# FX1 register map
Vendor: FTEL; File version: VP_FX1_V3.0_ISP_1.07
Registers are 32-bit, read-write, reset 0x0 unless marked. A register's access mark holds for its fields unless they carry their own. Offsets are from the block's base; [hi:lo] are bit positions; 'fields as' and 'values as' point back to an identical list; <NAME> marks a mode.

## ISP (part 2 of 4) — ISP FX1 v1.07; đủ register/field từ sheet Flat Registers của CSR. Địa chỉ base theo BSP VP_FX1_V3.0; không thay thế xác nhận map silicon.
Base 0x11000000
0x1808 NR_2D_STATUS ro — NR: block status. [access=ro]
  [0] BUSY — The 2D Noise-Reduction Block Busy 1 while the block itself holds pixels: the block's own busy, as defined in its MAS section. It can read 0 inside a frame (line fill, input gaps), so it does not show that a frame has drained; use COMMON_STATUS.BUSY = 0 for no frame in flight. Follow the block-specific configuration and LUT loading sequence; busy alone does not grant permission to rewrite live tables. [access=ro]
0x1A00 TNR_3D_CTRL — TNR_3D: reserved for a future temporal noise-reduction function. Register storage is present; writes have no image-processing effect in this MAS. [access=rw]
  [0] EN — Temporal NR Enable (not implemented) Reserved; no processing effect in this MAS. [access=rw]
0x1A04 TNR_3D_MTF_SEL — TNR_3D: motion transfer function preset. NOT IMPLEMENTED -- see TNR_3D_CTRL. [access=rw]
  [2:0] MTF — Motion Transfer Preset (not implemented) Reserved; no processing effect in this MAS. 0 = none, 1 = weak, 2 = medium, 3 = strong, 4 = aggressive. [access=rw]
0x1A08 TNR_3D_HIST_BASE — TNR_3D: DDR base address of the history frame. NOT IMPLEMENTED -- see TNR_3D_CTRL. [access=rw]
  [31:0] HIST_BASE_ADDR — History Frame Base Address (not implemented) Reserved; no processing effect in this MAS. [access=rw]
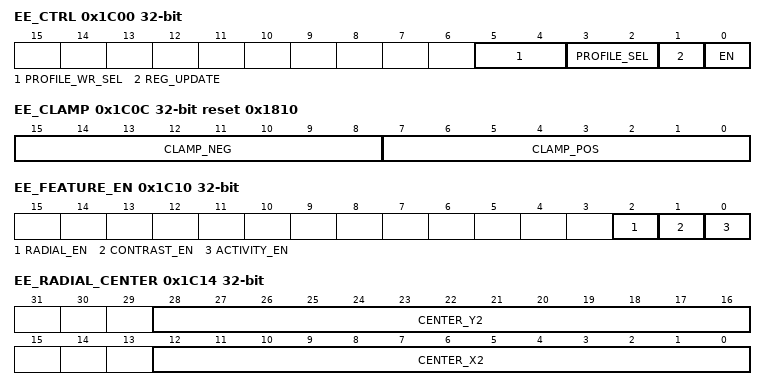
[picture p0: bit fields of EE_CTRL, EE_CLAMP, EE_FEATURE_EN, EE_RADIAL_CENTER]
0x1C00 EE_CTRL — EE: edge enhancement control. Sharpens by adding back a clamped, gain-shaped high-pass of the luma at two scales. [access=rw]
  [5:4] PROFILE_WR_SEL — Live resident programming/readback selector 0..2. Code 3 discards writes and reads profile 0. Not banked by TUNE_BANK. [access=rw]
  [3:2] PROFILE_SEL — Active Parameter Profile Select 0..2 select one of three resident tuning profiles. Captured at accepted window-centre SOF. Code 3 selects profile 0. Separate from PROFILE_WR_SEL. In profile mode, the ingress token supplies the bank enable and resident selection; local SOF uses that captured token. [access=rw]
  [1] REG_UPDATE — Reserved Update Control Readable/writable compatibility field; no explicit commit command. Enable, selected profile and scalar configuration are captured at the accepted window-centre SOF. In profile mode, the ingress token supplies the bank enable and resident selection; local SOF uses that captured token. [access=rw]
  [0] EN — Edge Enhancement Enable 1 = sharpen, 0 = delayed pass-through (the latency is unchanged). [access=rw]
0x1C04 EE_ALPHA reset 0x4000 — EE: fine-scale (3x3) sharpening strength. Resident scalar: PROFILE_WR_SEL selects both read and write; outside TUNE_BANK. Writes clear confirmation and are blocked while active, sealed, pending or referenced in profile mode. [access=rw]
  [15:0] ALPHA — Fine-Scale Sharpening Strength UQ1.15; 0x8000 = 1.0 and is the maximum. Larger values are clamped to 1.0 by the hardware rather than wrapping. External: the value is held outside the CSR block; the type is the bus behaviour. [access=rw]
0x1C08 EE_BETA reset 0x2000 — EE: coarse-scale (5x5) sharpening strength. Resident scalar: PROFILE_WR_SEL selects both read and write; outside TUNE_BANK. Writes clear confirmation and are blocked while active, sealed, pending or referenced in profile mode. [access=rw]
  [15:0] BETA — Coarse-Scale Sharpening Strength UQ1.15; 0x8000 = 1.0 and is the maximum, clamped as ALPHA is. The coarse term broadens the halo; usually set below ALPHA. External: the value is held outside the CSR block; the type is the bus behaviour. [access=rw]
0x1C0C EE_CLAMP reset 0x1810 — EE: limits on how far one pixel may be moved. The asymmetry is deliberate -- overshoot on the bright side of an edge is more visible than undershoot, so the positive clamp is usually the smaller. Resident scalar: PROFILE_WR_SEL selects both read and write; outside TUNE_BANK. Writes clear confirmation and are blocked while active, sealed, pending or referenced in profile mode. [access=rw]
  [15:8] CLAMP_NEG — Negative Correction Limit Largest negative correction, in 8-bit luma counts. External: the value is held outside the CSR block; the type is the bus behaviour. [access=rw]
  [7:0] CLAMP_POS — Positive Correction Limit Largest positive correction, in 8-bit luma counts. External: the value is held outside the CSR block; the type is the bus behaviour. [access=rw]
0x1C10 EE_FEATURE_EN — EE: optional activity, contrast and radial gain modulation. With all three disabled, correction still uses ALPHA/BETA and the always-applied luma LUT; disabled optional modulations contribute unity. Resident scalar: PROFILE_WR_SEL selects both read and write; outside TUNE_BANK. Writes clear confirmation and are blocked while active, sealed, pending or referenced in profile mode. [access=rw]
  [2] RADIAL_EN — Radial Modulation Enable 1 = modulate by distance from the image centre, using the R2 thresholds and the four radial gains. Lets the corners be sharpened differently from the centre. External: the value is held outside the CSR block; the type is the bus behaviour. [access=rw]
  [1] CONTRAST_EN — Contrast Modulation Enable 1 = modulate by local contrast, from the CPOS and CNEG LUTs. Separate tables for positive and negative excursions. External: the value is held outside the CSR block; the type is the bus behaviour. [access=rw]
  [0] ACTIVITY_EN — Activity Modulation Enable 1 = modulate by local activity, from the ACT LUT. Suppresses sharpening in flat areas, where it would only amplify noise. External: the value is held outside the CSR block; the type is the bus behaviour. [access=rw]
0x1C14 EE_RADIAL_CENTER — EE: centre of the radial falloff. Held at twice the coordinate so the centre can sit on a half-pixel, which matters for an even-sized frame whose true centre is between pixels. Resident scalar: PROFILE_WR_SEL selects both read and write; outside TUNE_BANK. Writes clear confirmation and are blocked while active, sealed, pending or referenced in profile mode. [access=rw]
  [28:16] CENTER_Y2 — Radial Centre Row (x2) Twice the centre row. External: the value is held outside the CSR block; the type is the bus behaviour. [access=rw]
  [12:0] CENTER_X2 — Radial Centre Column (x2) Twice the centre column. For a 1920-wide frame the centre is 1919/2, so this is 1919. External: the value is held outside the CSR block; the type is the bus behaviour. [access=rw]
0x1C18 EE_RADIAL_R2_TH0 — EE: radial zone boundary 0. Squared distance, so no square root is needed in the datapath. Resident scalar: PROFILE_WR_SEL selects both read and write; outside TUNE_BANK. Writes clear confirmation and are blocked while active, sealed, pending or referenced in profile mode. [access=rw]
  [26:0] R2_TH0 — Radial Zone 0 Boundary Squared radius at which zone 0 ends, in units of (2*pixel)^2 to match the doubled centre coordinates. External: the value is held outside the CSR block; the type is the bus behaviour. [access=rw]
0x1C1C EE_RADIAL_R2_TH1 — EE: radial zone boundary 1. Squared distance, so no square root is needed in the datapath. Resident scalar: PROFILE_WR_SEL selects both read and write; outside TUNE_BANK. Writes clear confirmation and are blocked while active, sealed, pending or referenced in profile mode. [access=rw]
  [26:0] R2_TH1 — Radial Zone 1 Boundary Squared radius at which zone 1 ends, in units of (2*pixel)^2 to match the doubled centre coordinates. Must not be below R2_TH0. Zones are tested in order and the first match wins; in profile mode SEAL rejects decreasing thresholds with RADIAL_EN=1 (INVALID). External: the value is held outside the CSR block; the type is the bus behaviour. [access=rw]
0x1C20 EE_RADIAL_R2_TH2 — EE: radial zone boundary 2. Squared distance, so no square root is needed in the datapath. Resident scalar: PROFILE_WR_SEL selects both read and write; outside TUNE_BANK. Writes clear confirmation and are blocked while active, sealed, pending or referenced in profile mode. [access=rw]
  [26:0] R2_TH2 — Radial Zone 2 Boundary Squared radius at which zone 2 ends, in units of (2*pixel)^2 to match the doubled centre coordinates. Must not be below R2_TH1. Zones are tested in order and the first match wins; in profile mode SEAL rejects decreasing thresholds with RADIAL_EN=1 (INVALID). External: the value is held outside the CSR block; the type is the bus behaviour. [access=rw]
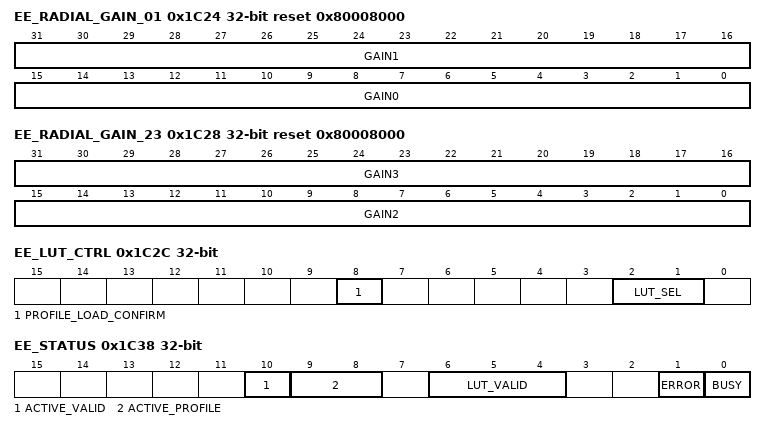
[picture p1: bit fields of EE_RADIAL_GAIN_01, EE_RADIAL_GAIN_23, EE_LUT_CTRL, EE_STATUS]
0x1C24 EE_RADIAL_GAIN_01 reset 0x80008000 — EE: radial gains for the innermost two zones. Resident scalar: PROFILE_WR_SEL selects both read and write; outside TUNE_BANK. Writes clear confirmation and are blocked while active, sealed, pending or referenced in profile mode. [access=rw]
  [31:16] GAIN1 — Radial Gain, Zone 1 UQ1.15 gain applied between R2_TH0 and R2_TH1; 0x8000 = 1.0 = no change. External: the value is held outside the CSR block; the type is the bus behaviour. [access=rw]
  [15:0] GAIN0 — Radial Gain, Innermost Zone UQ1.15 gain applied inside R2_TH0; 0x8000 = 1.0 = no change. External: the value is held outside the CSR block; the type is the bus behaviour. [access=rw]
0x1C28 EE_RADIAL_GAIN_23 reset 0x80008000 — EE: radial gains for the outer two zones. Resident scalar: PROFILE_WR_SEL selects both read and write; outside TUNE_BANK. Writes clear confirmation and are blocked while active, sealed, pending or referenced in profile mode. [access=rw]
  [31:16] GAIN3 — Radial Gain, Outermost Zone UQ1.15 gain applied beyond R2_TH2; 0x8000 = 1.0 = no change. External: the value is held outside the CSR block; the type is the bus behaviour. [access=rw]
  [15:0] GAIN2 — Radial Gain, Zone 2 UQ1.15 gain applied between R2_TH1 and R2_TH2; 0x8000 = 1.0 = no change. External: the value is held outside the CSR block; the type is the bus behaviour. [access=rw]
0x1C2C EE_LUT_CTRL — Live EE table selector and resident confirmation port. Scalar or LUT writes clear destination validity. Confirmation requires complete scalars/tables and mode-specific ownership: unreferenced in profile mode, disabled/idle in legacy mode. [access=mixed]
  [8] PROFILE_LOAD_CONFIRM wo write-1-sets — Confirm complete resident scalars and four LUTs. Profile mode: destination unreferenced by active/sealed/pending/in-flight state. Legacy: EE disabled/idle. Same-edge scalar/LUT write wins and leaves invalid. [access=w1p]
  [2:1] LUT_SEL — Gain Table Bank Select Also selects which bank EE_LUT_RDATA reads. 0x0 = LUMA (Luma table, 64 entries) 0x1 = ACTIVITY (Activity table, 64 entries) 0x2 = CONTRAST_POS (Contrast-positive table, 32 entries) 0x3 = CONTRAST_NEG (Contrast-negative table, 32 entries) [access=rw]
0x1C30 EE_LUT_ADDR — EE: gain table index. Auto-increments on every write to EE_LUT_WDATA. [access=rw]
  [5:0] LUT_ADDR — Gain Table Index Entry index. 0..63 for the luma and activity tables, 0..31 for the two contrast tables, where the top bit is ignored. [access=rw]
0x1C34 EE_LUT_WDATA — EE: gain table write port. [access=rw]
  [15:0] LUT_WDATA — Gain Table Write Data UQ1.15; 0x8000 = 1.0. Each selected profile owns its tables. RAM contents are undefined after reset: load every required entry before enabling EE. Values above 1.0 clamp on use. Readback uses EE_LUT_RDATA. [access=rw]
0x1C38 EE_STATUS — EE status. LUT_VALID reports confirmed profiles. An invalid selected profile bypasses correction without reading undefined SRAM contents. [access=mixed]
  [10] ACTIVE_VALID ro — One after a local SOF selected a confirmed resident; zero until then or after its validity is cleared. Separate from block busy and enable. [access=ro]
  [9:8] ACTIVE_PROFILE ro — Resident selection captured for the most recent accepted local EE SOF; does not follow PROFILE_WR_SEL. 0..2; zero after hard/common reset. [access=ro]
  [6:4] LUT_VALID ro — Confirmed resident scalars and four LUTs for profiles 0..2. Scalar/LUT writes or input-domain changes clear destination validity; hard reset and profile-mode common reset clear all. Invalid selected profile bypasses enhancement. [access=ro]
  [1] ERROR write-1-clears — Radial Gain Range Error Sticky W1C. Sets once per processed frame when EE and radial gain are enabled and an active-profile radial gain exceeds 1.5 (0xC000). The gain clamps to 1.5 on use. A simultaneous new event wins over clear. [access=w1c]
  [0] BUSY ro — EE Busy 1 while the block itself holds pixels: the block's own busy, as defined in its MAS section. It can read 0 inside a frame (line fill, input gaps), so it does not show that a frame has drained; use COMMON_STATUS.BUSY = 0 for no frame in flight. Profile mode protects active/sealed/pending/referenced residents; another unreferenced resident may be loaded. [access=ro]
0x1C3C EE_LUT_RDATA ro — EE: gain table readback selected by PROFILE_WR_SEL, EE_LUT_CTRL.LUT_SEL and EE_LUT_ADDR. Programming selector 3 reads profile 0. Contents are undefined until loaded. [access=ro]
  [15:0] RDATA — Gain Table Read Data Contents of the selected table entry. [access=ro]
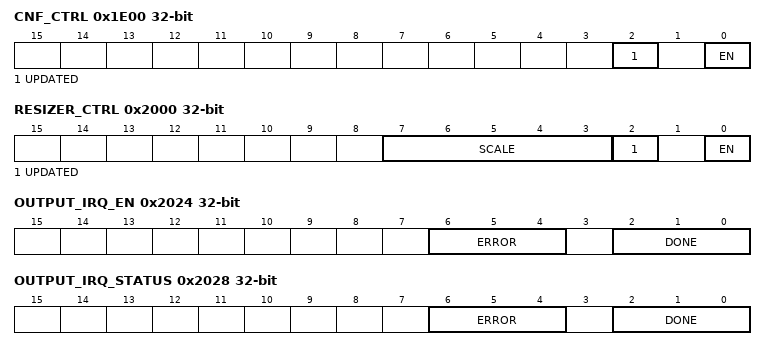
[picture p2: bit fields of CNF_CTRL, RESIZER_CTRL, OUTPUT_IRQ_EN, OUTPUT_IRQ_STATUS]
0x1E00 CNF_CTRL — CNF: chroma noise filter control. A 5x5 luma-guided filter (guided image filter, radius 2): chroma is fitted as a local linear function of luma, so noise is averaged in flat areas while chroma edges that coincide with luma edges are kept. [access=rw]
  [2] UPDATED — Reserved Update Control Readable/writable compatibility field with no commit effect. Enable and CNF_GF_EPS are sampled at accepted SOF. [access=rw]
  [0] EN — Chroma Noise Filter Enable 1 = filter chroma, 0 = pass through unchanged. [access=rw]
0x1E04 CNF_GF_EPS reset 0xC8 — CNF: guided-filter regularisation epsilon. Larger values smooth chroma more and keep fewer weak edges. [access=rw]
  [15:0] GF_EPS — Guided Filter Epsilon 0..65535, in 8-bit luma units squared. Windows whose luma variance is well below epsilon are smoothed; windows well above it keep chroma following luma. Every code is legal. [access=rw]
0x1E0C CNF_STRENGTH — CNF: reserved strength control. The specified filter uses enable and CNF_GF_EPS; this field has no processing effect. [access=rw]
  [1:0] MODE_STRENGTH — Filter Strength (not implemented) Reserved; no processing effect in this MAS. [access=rw]
0x1E10 CNF_STATUS ro — CNF: block status, read-only. [access=ro]
  [0] BUSY — Chroma Noise Filter Busy 1 while the block itself holds pixels: the block's own busy, as defined in its MAS section. It can read 0 inside a frame (line fill, input gaps), so it does not show that a frame has drained; use COMMON_STATUS.BUSY = 0 for no frame in flight. Follow the block-specific configuration and LUT loading sequence; busy alone does not grant permission to rewrite live tables. [access=ro]
0x2000 RESIZER_CTRL — CH0 NV12 output resizer control, maximum output 3840x2160. The unprefixed RESIZER_* registers belong to CH0. Input is the post-IQ crop for this channel; the crop may be larger than the output. No upscaling or custom target sizes. Reject invalid targets before DMA arm; no silent FullRes fallback. Wait for channel OUT_W/H to settle. [access=rw]
  [7:3] SCALE — CH0 NV12 preset selector [7:3]. 0=FullRes crop bypass; 1..14 established presets; 16=640x640, 17=640x384, 18=640x352, 19=512x512, 20=416x416, 21=320x320. Codes 15 and 22..31 reserved. Maximum output 3840x2160. Output must not exceed crop dimensions. No upscaling. [access=rw]
  [2] UPDATED — Legacy software update hint; readable storage with no commit effect. Active size, crop, enable and SCALE changes trigger geometry derivation. Custom-size words are reserved. Wait for OUT_W/H to settle before arming DMA; capture geometry at SOF. [access=rw]
  [0] EN — CH0 resizer enable. 1 selects SCALE; 0 bypasses scaling and preserves crop size. Both paths must fit the 3840x2160 output limit. Change geometry only after stop/drain; validate before DMA arm. [access=rw]
0x2004 RESIZER_CUSTOM_W ro — Deprecated target-size address. Reserved in ABI 1.07; reads zero and ignores writes. Programmable custom resizing is not supported. [access=ro]
  [31:0] RESERVED — Reads zero; writes ignored. [access=ro]
0x2008 RESIZER_CUSTOM_H ro — Deprecated target-size address. Reserved in ABI 1.07; reads zero and ignores writes. Programmable custom resizing is not supported. [access=ro]
  [31:0] RESERVED — Reads zero; writes ignored. [access=ro]
0x2014 RESIZER_OUT_W ro — Validated derived output dimension. Reset zero; may retain the last completed value while geometry is invalid. Check the channel GEOMETRY_STATUS before arming DMA. [access=ro]
  [12:0] OUT_WIDTH
0x2018 RESIZER_OUT_H ro — Validated derived output dimension. Reset zero; may retain the last completed value while geometry is invalid. Check the channel GEOMETRY_STATUS before arming DMA. [access=ro]
  [12:0] OUT_HEIGHT
0x201C RESIZER_STATUS ro — RESIZER: block status. [access=ro]
  [0] BUSY — Resizer Busy 1 while the block itself holds pixels: the block's own busy, as defined in its MAS section. It can read 0 inside a frame (line fill, input gaps), so it does not show that a frame has drained; use COMMON_STATUS.BUSY = 0 for no frame in flight. Follow the block-specific configuration and LUT loading sequence; busy alone does not grant permission to rewrite live tables. [access=ro]
0x2020 OUTPUT_ENABLE reset 0x1 — Enabled output channels. Defaults to CH0. Accepted SOF snapshots mask at distributor. Enabled channels share lossless backpressure. [access=rw]
  [2:0] CHANNELS — Bit 0 Preview NV12, bit 1 Video NV12, bit 2 NPU RGB888. Change only with input stopped and all output paths drained. [access=rw]
0x2024 OUTPUT_IRQ_EN — Per-output interrupt enables. [access=rw]
  [6:4] ERROR — Mask bit for error events. Field bits 0..2 correspond to CH0..CH2. One enables interrupt contribution; zero masks it. [access=rw]
  [2:0] DONE — Mask bit for completion events. Field bits 0..2 correspond to CH0..CH2. One enables interrupt contribution; zero masks it. [access=rw]
0x2028 OUTPUT_IRQ_STATUS write-1-clears — Per-output completion and error events; hardware set dominates software clear. Completion waits for write responses. [access=w1c]
  [6:4] ERROR write-1-clears — Sticky W1C error events; bit c sets when a recovery retires an enabled channel-c output without DONE. Field bits 0..2 correspond to CH0..CH2. Hardware set wins over clear. Clearing the event does not release buffer ownership. [access=w1c]
  [2:0] DONE write-1-clears — Sticky W1C completion events; bit c sets when channel c publishes ODMA_BUF_DONE. Field bits 0..2 correspond to CH0..CH2. Hardware set wins over clear. Clearing the event does not release buffer ownership. [access=w1c]
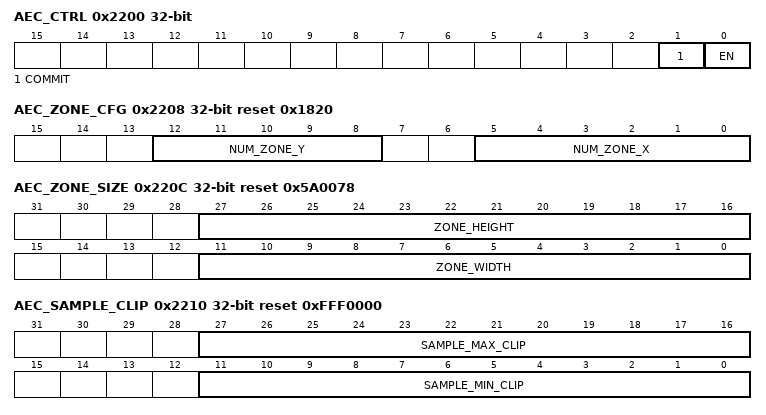
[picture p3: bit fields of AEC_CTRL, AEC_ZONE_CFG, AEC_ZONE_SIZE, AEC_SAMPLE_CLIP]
0x2200 AEC_CTRL — AEC: auto-exposure statistics control. The block only measures -- it does not drive exposure. Software reads the sums, counts and histogram and decides what to ask the sensor for. [access=mixed]
  [1] COMMIT write-1-sets — Configuration Commit Write 1 to transfer the shadowed enable, zone geometry, clip limits and thresholds at the next accepted ingress SOF. Self-clears on transfer. Active image height is captured per frame and is not shadowed by this command. [access=w1s]
  [0] EN — AE Statistics Enable 1 = accumulate statistics, 0 = idle. [access=rw]
0x2204 AEC_CONTEXT_ID — AEC: software tag carried with the statistics. Exposure changes take effect some frames after they are requested, so the tag is how software tells which request a result belongs to: write it here, read it back from AEC_RESULT_CONTEXT_ID with the matching frame. [access=rw]
  [31:0] CONTEXT_ID — Exposure Context Tag Software value captured at ingress SOF and associated with that frame. Write before admitting the frame; publication exposes it in AEC_RESULT_CONTEXT_ID. [access=rw]
0x2208 AEC_ZONE_CFG reset 0x1820 — AEC: zone grid. The frame is divided into a grid and each zone accumulates independently, so software can weight the metering however it likes. [access=rw]
  [12:8] NUM_ZONE_Y — Vertical Zone Count Vertical zones, 1..24. With the maximum grid there are 768 zones. [access=rw]
  [5:0] NUM_ZONE_X — Horizontal Zone Count Horizontal zones, 1..32. [access=rw]
0x220C AEC_ZONE_SIZE reset 0x5A0078 — AEC: nominal nonzero zone dimensions, 1..4095 each. Require (Nx-1)*zone_width < active_width <= Nx*zone_width and similarly in Y. The last zone covers the remainder. A single full-frame zone is legal; use authoritative 64-bit results rather than narrow low-bit projections. [access=rw]
  [27:16] ZONE_HEIGHT — Nominal Zone Height Nominal zone height in lines. [access=rw]
  [11:0] ZONE_WIDTH — Nominal Zone Width Nominal zone width in pixels. [access=rw]
0x2210 AEC_SAMPLE_CLIP reset 0xFFF0000 — Inclusive RAW12 Bayer sum/count qualification bounds, 0..4095. MIN <= MAX required. Extrema and histograms observe all measured samples independently of these clips. [access=rw]
  [27:16] SAMPLE_MAX_CLIP — Maximum qualifying RAW12 Bayer value, inclusive; valid range 0..4095; invalid values disable the frame measurement. [access=rw]
  [11:0] SAMPLE_MIN_CLIP — Minimum qualifying RAW12 Bayer value, inclusive; valid range 0..4095; invalid values disable the frame measurement. [access=rw]
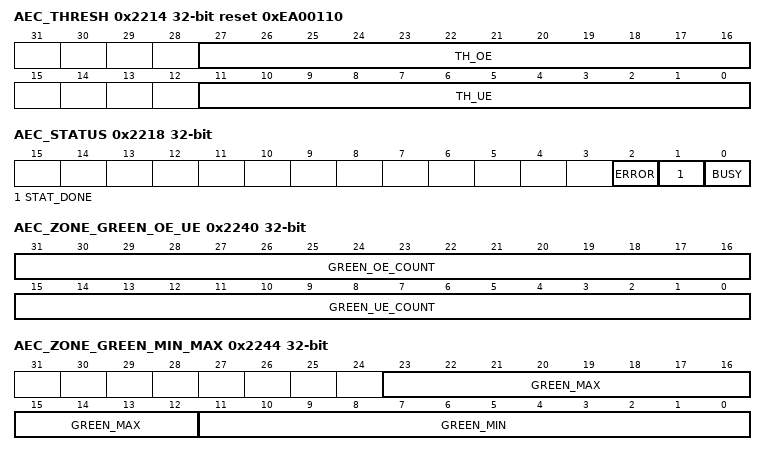
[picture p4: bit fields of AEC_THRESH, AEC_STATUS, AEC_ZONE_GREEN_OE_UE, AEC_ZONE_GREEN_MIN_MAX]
0x2214 AEC_THRESH reset 0xEA00110 — AEC: RAW12 Bayer threshold settings for per-zone over/under counts. OE increments for S>TH_OE; UE increments for S<TH_UE, independently of sum clipping. Any value above 4095 disables that frame measurement. [access=rw]
  [27:16] TH_OE — Strict RAW12 overexposure classification: sample > threshold. Startup 3744; programmable and sensor-calibrated. Require UE < OE. [access=rw]
  [11:0] TH_UE — Strict RAW12 underexposure classification: sample < threshold. Startup 272; programmable and sensor-calibrated. Require UE < OE. [access=rw]
0x2218 AEC_STATUS — AEC: block status. [access=mixed]
  [2] ERROR write-1-clears — AE Statistics Error (not implemented) Reads 0; not set by hardware. Software detects a missed frame from AEC_FRAME_ID. [access=w1c]
  [1] STAT_DONE write-1-clears — Statistics Ready Sticky W1C completion event. Results and identity publish atomically into a READY bank. ACQUIRE before reading; RELEASE after copying. Clearing STAT_DONE acknowledges the event and does not release the bank. Hardware completion wins over simultaneous clear. [access=w1c]
  [0] BUSY ro — AE Statistics Busy 1 = a frame is being accumulated. [access=ro]
0x221C AEC_FRAME_ID ro — AEC: ingress frame identifier of the leased result bank, read-only. [access=ro]
  [31:0] FRAME_ID — Shared ingress-SOF frame number of the leased statistics. First admitted frame after hard reset is 1; wraps modulo 2^32. Common and DMA soft resets preserve the counter. Metadata remains stable until RELEASE; no lease returns zero and sets the ownership error. [access=ro]
0x2220 AEC_RESULT_CONTEXT_ID ro — AEC: software context tag published with the leased statistics frame; stable until RELEASE. [access=ro]
  [31:0] CONTEXT_ID — Captured photometric configuration epoch for the measured frame. [access=ro]
0x2224 AEC_CHANNEL_SEL — Legacy readout selector: 0 aggregate Bayer statistics; 1..3 return zero rather than per-CFA results. This is not the AE source tap selector; use TUNE_AEC_SOURCE. [access=rw]
  [1:0] CHANNEL_SEL
0x2228 AEC_GLOBAL_SUM_LO ro — AEC: whole-frame qualified RAW12 Bayer sum, low word, read-only. Narrow readback is a low-bit modulo projection from the same acquired lease; use the 64-bit indirect readout for authoritative totals. No-lease reads return zero and set NO_LEASE. [access=ro]
  [31:0] GLOBAL_SUM_LO — Frame Sum, Low Word Bits [31:0] of the qualified sum. [access=ro]
0x222C AEC_GLOBAL_SUM_HI ro — AEC: whole-frame qualified RAW12 Bayer sum, high bits, read-only; retained width for map compatibility. Narrow readback is a low-bit modulo projection from the same acquired lease; use the 64-bit indirect readout for authoritative totals. No-lease reads return zero and set NO_LEASE. [access=ro]
  [0] GLOBAL_SUM_HI — Frame Sum, High Bit Bit [32] of the qualified sum. [access=ro]
0x2230 AEC_GLOBAL_COUNT ro — AEC: number of RAW12 Bayer samples contributing to the qualified global sum, read-only. The count excludes samples outside the inclusive clip bounds. Narrow readback is a low-bit modulo projection from the same acquired lease; use the 64-bit indirect readout for authoritative totals. No-lease reads return zero and set NO_LEASE. [access=ro]
  [22:0] GLOBAL_COUNT — Frame qualified RAW12 Bayer sample count. [access=ro]
0x2234 AEC_ZONE_ADDR — AEC: zone read selector, 0..767 in raster order. Narrow results project the same acquired bank as the 64-bit port. Two result banks preserve READY/LEASED data while another frame is collected; never reuse results before RELEASE. [access=rw]
  [9:0] ZONE_ADDR — Readout Zone Select Zone index 0..767, in raster order: y * num_zone_x + x. [access=rw]
0x2238 AEC_ZONE_SUM ro — AEC: qualified RAW12 Bayer sum for the selected zone, read-only. Narrow readback is a low-bit modulo projection from the same acquired lease; use the 64-bit indirect readout for authoritative totals. No-lease reads return zero and set NO_LEASE. [access=ro]
  [27:0] ZONE_SUM — Zone Sum Qualified sum for the zone at AEC_ZONE_ADDR. [access=ro]
0x223C AEC_ZONE_COUNT ro — AEC: qualified RAW12 Bayer sample count for the selected zone, read-only; wraps modulo 65,536. Narrow readback is a low-bit modulo projection from the same acquired lease; use the 64-bit indirect readout for authoritative totals. No-lease reads return zero and set NO_LEASE. [access=ro]
  [15:0] ZONE_COUNT — Qualified RAW12 Bayer count for selected zone; wraps modulo 65,536. [access=ro]
0x2240 AEC_ZONE_GREEN_OE_UE ro — AEC: legacy register name retained. Fields report RAW12 Bayer under/over counts for the selected zone, independent of clip qualification. Narrow readback is a low-bit modulo projection from the same acquired lease; use the 64-bit indirect readout for authoritative totals. No-lease reads return zero and set NO_LEASE. [access=ro]
  [31:16] GREEN_OE_COUNT — Zone Over-Exposed Count Observed RAW12 Bayer values above TH_OE in this zone; wraps modulo 65,536. [access=ro]
  [15:0] GREEN_UE_COUNT — Zone Under-Exposed Count Observed RAW12 Bayer values below TH_UE in this zone; wraps modulo 65,536. [access=ro]
0x2244 AEC_ZONE_GREEN_MIN_MAX ro — AEC: legacy register name retained. Fields report the leased zone minimum/maximum observed RAW12 Bayer; an empty zone reads min=4095,max=0. Without a lease the word reads zero and sets NO_LEASE. [access=ro]
  [23:12] GREEN_MAX — Zone maximum observed RAW12 Bayer. Empty zone reads 0. [access=ro]
  [11:0] GREEN_MIN — Zone minimum observed RAW12 Bayer. Empty zone reads 4095; zero without a lease. [access=ro]
0x2248 AEC_HIST_ADDR — AEC: select one of 64 RAW12 Bayer histogram bins; bin n represents Bayer sample values 64n through 64n+63. [access=rw]
  [5:0] HIST_ADDR — Bin index 0..63; bin n covers RAW12 Bayer values 64n..64n+63. [access=rw]
0x224C AEC_HIST_DATA ro — AEC: population of the selected bin in the 64-bin histogram of all observed RAW12 Bayer samples, read-only. Narrow readback is a low-bit modulo projection from the same acquired lease; use the 64-bit indirect readout for authoritative totals. No-lease reads return zero and set NO_LEASE. [access=ro]
  [22:0] HIST_COUNT — Histogram population. Bin index is normalized RAW12 sample[11:6] (sample >> 6); full-frame count supports up to 3840x2160. [access=ro]
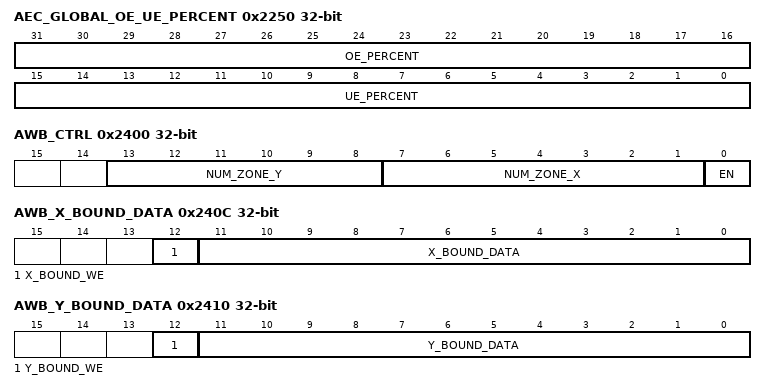
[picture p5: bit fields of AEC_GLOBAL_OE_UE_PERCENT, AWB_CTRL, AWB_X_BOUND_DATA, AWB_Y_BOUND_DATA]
0x2250 AEC_GLOBAL_OE_UE_PERCENT ro — AEC: global over- and under-exposed sample percentages of the leased frame, read-only. Each is floor(25600 * count / (width * height)) in unsigned Q7.8 (value / 256 = percent; 100% = 0x6400), where count is the global OE or UE count and width * height is every observed RAW12 Bayer sample of the frame. Published together with the other AEC results. No-lease reads return zero and set NO_LEASE. [access=ro]
  [31:16] OE_PERCENT — Over-exposed percentage, Q7.8: floor(25600 * OE_COUNT / (W * H)); 0..0x6400. [access=ro]
  [15:0] UE_PERCENT — Under-exposed percentage, Q7.8: floor(25600 * UE_COUNT / (W * H)); 0..0x6400. [access=ro]
0x2400 AWB_CTRL — AWB: non-blocking post-BPC Bayer-cell statistics. Each accepted 2x2 RGGB cell contributes R, rounded-average green and B once on the uniform cell grid. [access=rw]
  [13:8] NUM_ZONE_Y — Vertical zone count over active cell rows (active height/2). [access=rw]
  [7:1] NUM_ZONE_X — Horizontal zone count over active cell columns (active width/2). [access=rw]
  [0] EN — Enable Bayer-cell AWB measurement; invalid enabled geometry is skipped and reported. [access=rw]
0x2404 AWB_X_BOUND_ADDR — AWB_X_BOUND_ADDR: reserved boundary-table control. Uniform boundaries are derived from AWB_CTRL zone counts and active geometry; writes have no processing effect. [access=rw]
  [5:0] X_BOUND_ADDR — Horizontal Boundary Index (not implemented) Reserved; no processing effect in this MAS. [access=rw]
0x2408 AWB_Y_BOUND_ADDR — AWB_Y_BOUND_ADDR: reserved boundary-table control. Uniform boundaries are derived from AWB_CTRL zone counts and active geometry; writes have no processing effect. [access=rw]
  [4:0] Y_BOUND_ADDR — Vertical Boundary Index (not implemented) Reserved; no processing effect in this MAS. [access=rw]
0x240C AWB_X_BOUND_DATA — AWB_X_BOUND_DATA: reserved boundary-table control. Uniform boundaries are derived from AWB_CTRL zone counts and active geometry; writes have no processing effect. [access=rw]
  [12] X_BOUND_WE — Horizontal Boundary Write Enable (not implemented) Reserved; no processing effect in this MAS. [access=rw]
  [11:0] X_BOUND_DATA — Horizontal Boundary Value (not implemented) Reserved; no processing effect in this MAS. [access=rw]
0x2410 AWB_Y_BOUND_DATA — AWB_Y_BOUND_DATA: reserved boundary-table control. Uniform boundaries are derived from AWB_CTRL zone counts and active geometry; writes have no processing effect. [access=rw]
  [12] Y_BOUND_WE — Vertical Boundary Write Enable (not implemented) Reserved; no processing effect in this MAS. [access=rw]
  [11:0] Y_BOUND_DATA — Vertical Boundary Value (not implemented) Reserved; no processing effect in this MAS. [access=rw]
0x2414 AWB_GLOBAL_SUM_R_H ro — AWB: whole-frame sum of Rcell over qualified Bayer cells; read-only. [access=ro]
  [2:0] GLOBAL_SUM_R_H — Frame Red Sum, High Bits Bits [34:32] of the qualified red sum. [access=ro]
0x2418 AWB_GLOBAL_SUM_R_L ro — AWB: whole-frame sum of Rcell over qualified Bayer cells; read-only. [access=ro]
  [31:0] GLOBAL_SUM_R_L — Frame Red Sum, Low Word Bits [31:0] of the qualified red sum. [access=ro]
0x241C AWB_GLOBAL_SUM_G_H ro — AWB: whole-frame sum of Gcell over qualified Bayer cells; read-only. [access=ro]
  [2:0] GLOBAL_SUM_G_H — Frame Green Sum, High Bits Bits [34:32] of the qualified green sum. [access=ro]
0x2420 AWB_GLOBAL_SUM_G_L ro — AWB: whole-frame sum of Gcell over qualified Bayer cells; read-only. [access=ro]
  [31:0] GLOBAL_SUM_G_L — Frame Green Sum, Low Word Bits [31:0] of the qualified green sum. [access=ro]
0x2424 AWB_GLOBAL_SUM_B_H ro — AWB: whole-frame sum of Bcell over qualified Bayer cells; read-only. [access=ro]
  [2:0] GLOBAL_SUM_B_H — Frame Blue Sum, High Bits Bits [34:32] of the qualified blue sum. [access=ro]
0x2428 AWB_GLOBAL_SUM_B_L ro — AWB: whole-frame sum of Bcell over qualified Bayer cells; read-only. [access=ro]
  [31:0] GLOBAL_SUM_B_L — Frame Blue Sum, Low Word Bits [31:0] of the qualified blue sum. [access=ro]
0x242C AWB_GLOBAL_COUNT ro — AWB: number of qualified Bayer cells contributing to each whole-frame channel sum, read-only. [access=ro]
  [22:0] GLOBAL_COUNT — Qualified-cell count for the frame; one increment per accepted 2x2 cell. [access=ro]
0x2430 AWB_ZONE_ADDR — AWB: leased-bank zone read selector. Raster index y*READ_NUM_ZONE_X+x using the captured grid in AWB_RESULT_STATUS. Allow one core clock after selecting an address. Out-of-grid and untouched entries read zero. [access=rw]
  [10:0] ZONE_ADDR — Readout Zone Select Zone index in raster order. [access=rw]
0x2434 AWB_ZONE_SUM_R_H ro — AWB: selected-zone sum of Rcell over qualified Bayer cells; read-only. [access=ro]
  [2:0] ZONE_SUM_R_H — Zone Red Sum, High Bits Bits [34:32] of the zone's red sum. [access=ro]
0x2438 AWB_ZONE_SUM_R_L ro — AWB: selected-zone sum of Rcell over qualified Bayer cells; read-only. [access=ro]
  [31:0] ZONE_SUM_R_L — Zone Red Sum, Low Word Bits [31:0] of the zone's red sum. [access=ro]
0x243C AWB_ZONE_SUM_G_H ro — AWB: selected-zone sum of Gcell over qualified Bayer cells; read-only. [access=ro]
  [2:0] ZONE_SUM_G_H — Zone Green Sum, High Bits Bits [34:32] of the zone's green sum. [access=ro]
0x2440 AWB_ZONE_SUM_G_L ro — AWB: selected-zone sum of Gcell over qualified Bayer cells; read-only. [access=ro]
  [31:0] ZONE_SUM_G_L — Zone Green Sum, Low Word Bits [31:0] of the zone's green sum. [access=ro]
0x2444 AWB_ZONE_SUM_B_H ro — AWB: selected-zone sum of Bcell over qualified Bayer cells; read-only. [access=ro]
  [2:0] ZONE_SUM_B_H — Zone Blue Sum, High Bits Bits [34:32] of the zone's blue sum. [access=ro]
0x2448 AWB_ZONE_SUM_B_L ro — AWB: selected-zone sum of Bcell over qualified Bayer cells; read-only. [access=ro]
  [31:0] ZONE_SUM_B_L — Zone Blue Sum, Low Word Bits [31:0] of the zone's blue sum. [access=ro]
0x244C AWB_ZONE_COUNT ro — AWB: qualified Bayer-cell count for the selected zone, read-only. [access=ro]
  [22:0] ZONE_COUNT — Qualified-cell count for the selected zone; one increment per accepted cell. [access=ro]
0x2450 AWB_STATUS write-1-clears — AWB: sticky completion-event status. Completion does not grant read ownership; acquire the READY bank using AWB_RESULT_CTRL before reading results. [access=w1c]
  [0] STAT_DONE write-1-clears — Statistics Ready W1C event set when a complete result bank becomes READY. Clearing it neither acquires nor releases a bank. A simultaneous completion wins over clear. Poll READY_COUNT to detect queued results independently of this event. [access=w1c]
0x2454 AWB_UNDEREXPOSED_LIMIT — AWB: strict lower qualification limit in 12-bit post-BPC Bayer code units. A cell is rejected if any of its four samples is <= this value. [access=rw]
  [11:0] UNDEREXPOSED_LIMIT — 12-bit raw Bayer limit; all four cell samples must be strictly greater. [access=rw]
0x2458 AWB_SATURATION_LIMIT reset 0xFFF — AWB: strict upper qualification limit in 12-bit post-BPC Bayer code units. A cell is rejected if any of its four samples is >= this value. [access=rw]
  [11:0] SATURATION_LIMIT — 12-bit raw Bayer limit; all four cell samples must be strictly less. [access=rw]
0x245C AWB_CONTEXT_ID — AWB: illumination/color-control software context captured at ingress SOF with the frame configuration. [access=rw]
  [31:0] CONTEXT_ID — Opaque software context captured at ingress SOF and published with that frame result. [access=rw]
0x2460 AWB_RESULT_CONTEXT_ID ro — AWB: AWB_CONTEXT_ID captured with the immutable ingress-SOF statistics configuration, read-only. [access=ro]
  [31:0] CONTEXT_ID — AWB_CONTEXT_ID captured at ingress SOF for the frame whose result is leased. [access=ro]
0x2464 AWB_FRAME_ID ro — AWB: ingress frame identifier of the leased result bank, read-only. [access=ro]
  fields as AEC_FRAME_ID
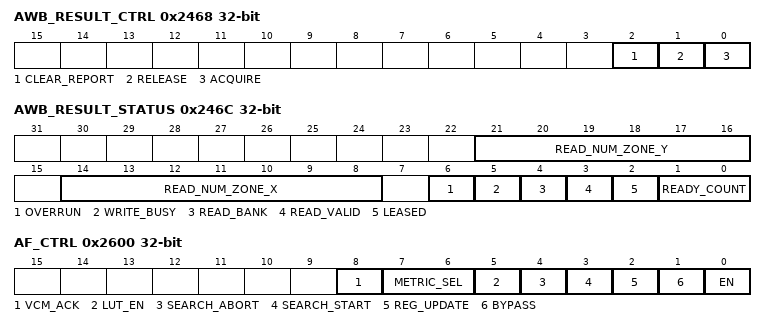
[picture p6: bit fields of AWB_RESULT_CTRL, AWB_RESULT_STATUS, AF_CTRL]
0x2468 AWB_RESULT_CTRL wo write-1-sets — AWB: one-clock write-one ownership/report commands, qualified by byte strobes. Reads return zero; reserved bits are ignored. RELEASE wins over simultaneous ACQUIRE. New loss events win over CLEAR_REPORT. [access=w1p]
  [2] CLEAR_REPORT write-1-sets — Clear OVERRUN and DROP_COUNT only. One-clock command; reads zero. Does not release results or clear STAT_DONE. A simultaneous new loss sets OVERRUN and increments the cleared count. [access=w1p]
  [1] RELEASE write-1-sets — Release the LEASED bank to FREE. One-clock command; reads zero. No effect without a lease. A released bank is eligible for admission on the following edge. [access=w1p]
  [0] ACQUIRE write-1-sets — Acquire the oldest READY bank for software readout. One-clock command; reads zero. No effect if no READY result or a lease already exists. Confirm READ_VALID before reading; allow one clock before zone reads. [access=w1p]
0x246C AWB_RESULT_STATUS ro — AWB: ownership status. Two result banks; at most one lease. Ready/leased banks are immutable. All reserved bits read zero. [access=ro]
  [21:16] READ_NUM_ZONE_Y — Vertical grid count captured with the leased bank; zero without a lease. [access=ro]
  [14:8] READ_NUM_ZONE_X — Horizontal grid count captured with the leased bank; zero without a lease. [access=ro]
  [6] OVERRUN — Sticky report for bank exhaustion, illegal geometry or ingress-context overflow. No new interrupt; clear with CLEAR_REPORT. [access=ro]
  [5] WRITE_BUSY — 1 while a bank is WRITING, including final accumulation drain. [access=ro]
  [4] READ_BANK — Index of leased result bank; zero without a lease. [access=ro]
  [3] READ_VALID — Equals LEASED; result reads return zero when clear. [access=ro]
  [2] LEASED — 1 when software holds a result bank. [access=ro]
  [1:0] READY_COUNT — Number of complete READY banks, 0..2. [access=ro]
0x2470 AWB_DROP_COUNT ro — AWB: number of lost enabled measurements. Disabled frames do not increment. Count each lost measurement once; simultaneous distinct losses both count. [access=ro]
  [31:0] DROP_COUNT — Saturating 32-bit count, maximum 0xFFFFFFFF. Clears on hard/common soft reset or CLEAR_REPORT. DMA-only reset preserves reporting. [access=ro]
0x2600 AF_CTRL — AF: auto-focus statistics control. Only the enable is implemented -- the block measures a focus score per zone. The search and VCM fields below have no hardware behind them. [access=mixed]
  [8] VCM_ACK — VCM Acknowledge (not implemented) Reserved; no processing effect in this MAS. [access=rw]
  [7:6] METRIC_SEL — Focus Metric Select (not implemented) No hardware behind this field (feature absent): the block computes one focus metric, which is not selectable. [access=rw]
  [5] LUT_EN — Position LUT Enable (not implemented) Reserved; no processing effect in this MAS. [access=rw]
  [4] SEARCH_ABORT write-1-sets — Abort Focus Search (not implemented) Reserved; no processing effect in this MAS. [access=w1s]
  [3] SEARCH_START write-1-sets — Start Focus Search (not implemented) No hardware behind this bit (feature absent): there is no search engine. [access=w1s]
  [2] REG_UPDATE — Configuration Commit (not implemented) Reserved; no processing effect in this MAS. [access=rw]
  [1] BYPASS — AF Bypass (not implemented) No hardware behind this bit (feature absent); use EN. [access=rw]
  [0] EN — AF Statistics Enable 1 = accumulate focus statistics, 0 = idle. [access=rw]
